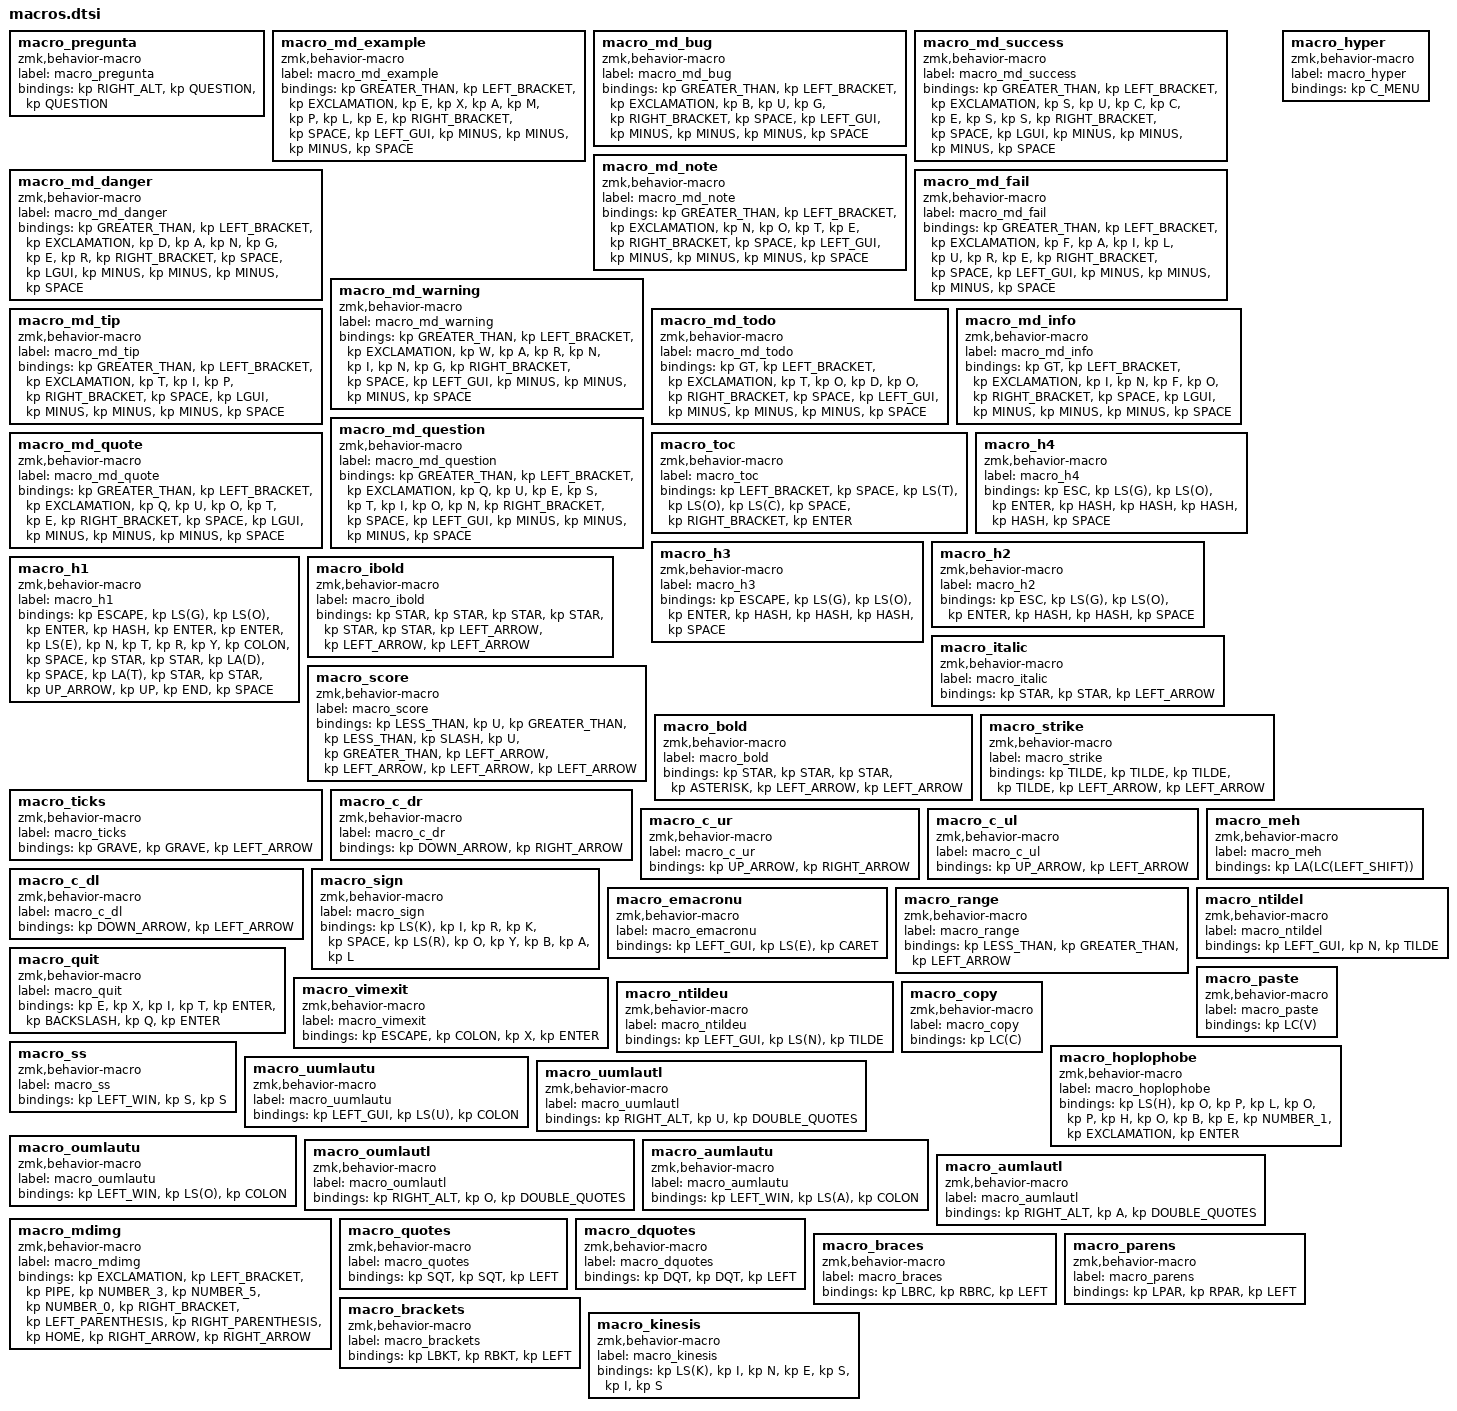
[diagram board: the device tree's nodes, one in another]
macro_pregunta: macro_pregunta{
compatible = "zmk,behavior-macro";
label = "macro_pregunta";
#binding-cells = <0>;
bindings = <&kp RIGHT_ALT>, <&kp QUESTION>, <&kp QUESTION>;
};
macro_md_example: macro_md_example{
compatible = "zmk,behavior-macro";
label = "macro_md_example";
#binding-cells = <0>;
bindings = <&kp GREATER_THAN>, <&kp LEFT_BRACKET>, <&kp EXCLAMATION>, <&kp E>, <&kp X>, <&kp A>, <&kp M>, <&kp P>, <&kp L>, <&kp E>, <&kp RIGHT_BRACKET>, <&kp SPACE>, <&kp LEFT_GUI>, <&kp MINUS>, <&kp MINUS>, <&kp MINUS>, <&kp SPACE>;
};
macro_md_bug: macro_md_bug{
compatible = "zmk,behavior-macro";
label = "macro_md_bug";
#binding-cells = <0>;
bindings = <&kp GREATER_THAN>, <&kp LEFT_BRACKET>, <&kp EXCLAMATION>, <&kp B>, <&kp U>, <&kp G>, <&kp RIGHT_BRACKET>, <&kp SPACE>, <&kp LEFT_GUI>, <&kp MINUS>, <&kp MINUS>, <&kp MINUS>, <&kp SPACE>;
};
macro_md_success: macro_md_success{
compatible = "zmk,behavior-macro";
label = "macro_md_success";
#binding-cells = <0>;
bindings = <&kp GREATER_THAN>, <&kp LEFT_BRACKET>, <&kp EXCLAMATION>, <&kp S>, <&kp U>, <&kp C>, <&kp C>, <&kp E>, <&kp S>, <&kp S>, <&kp RIGHT_BRACKET>, <&kp SPACE>, <&kp LGUI>, <&kp MINUS>, <&kp MINUS>, <&kp MINUS>, <&kp SPACE>;
};
macro_md_note: macro_md_note{
compatible = "zmk,behavior-macro";
label = "macro_md_note";
#binding-cells = <0>;
bindings = <&kp GREATER_THAN>, <&kp LEFT_BRACKET>, <&kp EXCLAMATION>, <&kp N>, <&kp O>, <&kp T>, <&kp E>, <&kp RIGHT_BRACKET>, <&kp SPACE>, <&kp LEFT_GUI>, <&kp MINUS>, <&kp MINUS>, <&kp MINUS>, <&kp SPACE>;
};
macro_md_danger: macro_md_danger{
compatible = "zmk,behavior-macro";
label = "macro_md_danger";
#binding-cells = <0>;
bindings = <&kp GREATER_THAN>, <&kp LEFT_BRACKET>, <&kp EXCLAMATION>, <&kp D>, <&kp A>, <&kp N>, <&kp G>, <&kp E>, <&kp R>, <&kp RIGHT_BRACKET>, <&kp SPACE>, <&kp LGUI>, <&kp MINUS>, <&kp MINUS>, <&kp MINUS>, <&kp SPACE>;
};
macro_md_fail: macro_md_fail{
compatible = "zmk,behavior-macro";
label = "macro_md_fail";
#binding-cells = <0>;
bindings = <&kp GREATER_THAN>, <&kp LEFT_BRACKET>, <&kp EXCLAMATION>, <&kp F>, <&kp A>, <&kp I>, <&kp L>, <&kp U>, <&kp R>, <&kp E>, <&kp RIGHT_BRACKET>, <&kp SPACE>, <&kp LEFT_GUI>, <&kp MINUS>, <&kp MINUS>, <&kp MINUS>, <&kp SPACE>;
};
macro_md_warning: macro_md_warning{
compatible = "zmk,behavior-macro";
label = "macro_md_warning";
#binding-cells = <0>;
bindings = <&kp GREATER_THAN>, <&kp LEFT_BRACKET>, <&kp EXCLAMATION>, <&kp W>, <&kp A>, <&kp R>, <&kp N>, <&kp I>, <&kp N>, <&kp G>, <&kp RIGHT_BRACKET>, <&kp SPACE>, <&kp LEFT_GUI>, <&kp MINUS>, <&kp MINUS>, <&kp MINUS>, <&kp SPACE>;
};
macro_md_tip: macro_md_tip{
compatible = "zmk,behavior-macro";
label = "macro_md_tip";
#binding-cells = <0>;
bindings = <&kp GREATER_THAN>, <&kp LEFT_BRACKET>, <&kp EXCLAMATION>, <&kp T>, <&kp I>, <&kp P>, <&kp RIGHT_BRACKET>, <&kp SPACE>, <&kp LGUI>, <&kp MINUS>, <&kp MINUS>, <&kp MINUS>, <&kp SPACE>;
};
macro_md_todo: macro_md_todo{
compatible = "zmk,behavior-macro";
label = "macro_md_todo";
#binding-cells = <0>;
bindings = <&kp GT>, <&kp LEFT_BRACKET>, <&kp EXCLAMATION>, <&kp T>, <&kp O>, <&kp D>, <&kp O>, <&kp RIGHT_BRACKET>, <&kp SPACE>, <&kp LEFT_GUI>, <&kp MINUS>, <&kp MINUS>, <&kp MINUS>, <&kp SPACE>;
};
macro_md_info: macro_md_info{
compatible = "zmk,behavior-macro";
label = "macro_md_info";
#binding-cells = <0>;
bindings = <&kp GT>, <&kp LEFT_BRACKET>, <&kp EXCLAMATION>, <&kp I>, <&kp N>, <&kp F>, <&kp O>, <&kp RIGHT_BRACKET>, <&kp SPACE>, <&kp LGUI>, <&kp MINUS>, <&kp MINUS>, <&kp MINUS>, <&kp SPACE>;
};
macro_md_question: macro_md_question{
compatible = "zmk,behavior-macro";
label = "macro_md_question";
#binding-cells = <0>;
bindings = <&kp GREATER_THAN>, <&kp LEFT_BRACKET>, <&kp EXCLAMATION>, <&kp Q>, <&kp U>, <&kp E>, <&kp S>, <&kp T>, <&kp I>, <&kp O>, <&kp N>, <&kp RIGHT_BRACKET>, <&kp SPACE>, <&kp LEFT_GUI>, <&kp MINUS>, <&kp MINUS>, <&kp MINUS>, <&kp SPACE>;
};
macro_md_quote: macro_md_quote{
compatible = "zmk,behavior-macro";
label = "macro_md_quote";
#binding-cells = <0>;
bindings = <&kp GREATER_THAN>, <&kp LEFT_BRACKET>, <&kp EXCLAMATION>, <&kp Q>, <&kp U>, <&kp O>, <&kp T>, <&kp E>, <&kp RIGHT_BRACKET>, <&kp SPACE>, <&kp LGUI>, <&kp MINUS>, <&kp MINUS>, <&kp MINUS>, <&kp SPACE>;
};
macro_toc: macro_toc{
compatible = "zmk,behavior-macro";
label = "macro_toc";
#binding-cells = <0>;
bindings = <&kp LEFT_BRACKET>, <&kp SPACE>, <&kp LS(T)>, <&kp LS(O)>, <&kp LS(C)>, <&kp SPACE>, <&kp RIGHT_BRACKET>, <&kp ENTER>;
};
macro_h4: macro_h4{
compatible = "zmk,behavior-macro";
label = "macro_h4";
#binding-cells = <0>;
bindings = <&kp ESC>, <&kp LS(G)>, <&kp LS(O)>, <&kp ENTER>, <&kp HASH>, <&kp HASH>, <&kp HASH>, <&kp HASH>, <&kp SPACE>;
};
macro_h3: macro_h3{
compatible = "zmk,behavior-macro";
label = "macro_h3";
#binding-cells = <0>;
bindings = <&kp ESCAPE>, <&kp LS(G)>, <&kp LS(O)>, <&kp ENTER>, <&kp HASH>, <&kp HASH>, <&kp HASH>, <&kp SPACE>;
};
macro_h2: macro_h2{
compatible = "zmk,behavior-macro";
label = "macro_h2";
#binding-cells = <0>;
bindings = <&kp ESC>, <&kp LS(G)>, <&kp LS(O)>, <&kp ENTER>, <&kp HASH>, <&kp HASH>, <&kp SPACE>;
};
macro_h1: macro_h1{
compatible = "zmk,behavior-macro";
label = "macro_h1";
#binding-cells = <0>;
bindings = <&kp ESCAPE>, <&kp LS(G)>, <&kp LS(O)>, <&kp ENTER>, <&kp HASH>, <&kp ENTER>, <&kp ENTER>, <&kp LS(E)>, <&kp N>, <&kp T>, <&kp R>, <&kp Y>, <&kp COLON>, <&kp SPACE>, <&kp STAR>, <&kp STAR>, <&kp LA(D)>, <&kp SPACE>, <&kp LA(T)>, <&kp STAR>, <&kp STAR>, <&kp UP_ARROW>, <&kp UP>, <&kp END>, <&kp SPACE>;
};
macro_ibold: macro_ibold{
compatible = "zmk,behavior-macro";
label = "macro_ibold";
#binding-cells = <0>;
bindings = <&kp STAR>, <&kp STAR>, <&kp STAR>, <&kp STAR>, <&kp STAR>, <&kp STAR>, <&kp LEFT_ARROW>, <&kp LEFT_ARROW>, <&kp LEFT_ARROW>;
};
macro_italic: macro_italic{
compatible = "zmk,behavior-macro";
label = "macro_italic";
#binding-cells = <0>;
bindings = <&kp STAR>, <&kp STAR>, <&kp LEFT_ARROW>;
};
macro_score: macro_score{
compatible = "zmk,behavior-macro";
label = "macro_score";
#binding-cells = <0>;
bindings = <&kp LESS_THAN>, <&kp U>, <&kp GREATER_THAN>, <&kp LESS_THAN>, <&kp SLASH>, <&kp U>, <&kp GREATER_THAN>, <&kp LEFT_ARROW>, <&kp LEFT_ARROW>, <&kp LEFT_ARROW>, <&kp LEFT_ARROW>;
};
macro_bold: macro_bold{
compatible = "zmk,behavior-macro";
label = "macro_bold";
#binding-cells = <0>;
bindings = <&kp STAR>, <&kp STAR>, <&kp STAR>, <&kp ASTERISK>, <&kp LEFT_ARROW>, <&kp LEFT_ARROW>;
};
macro_strike: macro_strike{
compatible = "zmk,behavior-macro";
label = "macro_strike";
#binding-cells = <0>;
bindings = <&kp TILDE>, <&kp TILDE>, <&kp TILDE>, <&kp TILDE>, <&kp LEFT_ARROW>, <&kp LEFT_ARROW>;
};
macro_ticks: macro_ticks{
compatible = "zmk,behavior-macro";
label = "macro_ticks";
#binding-cells = <0>;
bindings = <&kp GRAVE>, <&kp GRAVE>, <&kp LEFT_ARROW>;
};
macro_c_dr: macro_c_dr{
compatible = "zmk,behavior-macro";
label = "macro_c_dr";
#binding-cells = <0>;
bindings = <&kp DOWN_ARROW>, <&kp RIGHT_ARROW>;
};
macro_c_ur: macro_c_ur{
compatible = "zmk,behavior-macro";
label = "macro_c_ur";
#binding-cells = <0>;
bindings = <&kp UP_ARROW>, <&kp RIGHT_ARROW>;
};
macro_c_ul: macro_c_ul{
compatible = "zmk,behavior-macro";
label = "macro_c_ul";
#binding-cells = <0>;
bindings = <&kp UP_ARROW>, <&kp LEFT_ARROW>;
};
macro_c_dl: macro_c_dl{
compatible = "zmk,behavior-macro";
label = "macro_c_dl";
#binding-cells = <0>;
bindings = <&kp DOWN_ARROW>, <&kp LEFT_ARROW>;
};
macro_sign: macro_sign{
compatible = "zmk,behavior-macro";
label = "macro_sign";
#binding-cells = <0>;
bindings = <&kp LS(K)>, <&kp I>, <&kp R>, <&kp K>, <&kp SPACE>, <&kp LS(R)>, <&kp O>, <&kp Y>, <&kp B>, <&kp A>, <&kp L>;
};
macro_emacronu: macro_emacronu{
compatible = "zmk,behavior-macro";
label = "macro_emacronu";
#binding-cells = <0>;
bindings = <&kp LEFT_GUI>, <&kp LS(E)>, <&kp CARET>;
};
macro_range: macro_range{
compatible = "zmk,behavior-macro";
label = "macro_range";
#binding-cells = <0>;
bindings = <&kp LESS_THAN>, <&kp GREATER_THAN>, <&kp LEFT_ARROW>;
};
macro_hyper: macro_hyper{
compatible = "zmk,behavior-macro";
label = "macro_hyper";
#binding-cells = <0>;
bindings = <&kp C_MENU>;
};
macro_meh: macro_meh{
compatible = "zmk,behavior-macro";
label = "macro_meh";
#binding-cells = <0>;
bindings = <&kp LA(LC(LEFT_SHIFT))>;
};
macro_quit: macro_quit{
compatible = "zmk,behavior-macro";
label = "macro_quit";
#binding-cells = <0>;
bindings = <&kp E>, <&kp X>, <&kp I>, <&kp T>, <&kp ENTER>, <&kp BACKSLASH>, <&kp Q>, <&kp ENTER>;
};
macro_vimexit: macro_vimexit{
compatible = "zmk,behavior-macro";
label = "macro_vimexit";
#binding-cells = <0>;
bindings = <&kp ESCAPE>, <&kp COLON>, <&kp X>, <&kp ENTER>;
};
macro_ntildeu: macro_ntildeu{
compatible = "zmk,behavior-macro";
label = "macro_ntildeu";
#binding-cells = <0>;
bindings = <&kp LEFT_GUI>, <&kp LS(N)>, <&kp TILDE>;
};
macro_ntildel: macro_ntildel{
compatible = "zmk,behavior-macro";
label = "macro_ntildel";
#binding-cells = <0>;
bindings = <&kp LEFT_GUI>, <&kp N>, <&kp TILDE>;
};
macro_paste: macro_paste{
compatible = "zmk,behavior-macro";
label = "macro_paste";
#binding-cells = <0>;
bindings = <&kp LC(V)>;
};
macro_copy: macro_copy{
compatible = "zmk,behavior-macro";
label = "macro_copy";
#binding-cells = <0>;
bindings = <&kp LC(C)>;
};
macro_hoplophobe: macro_hoplophobe{
compatible = "zmk,behavior-macro";
label = "macro_hoplophobe";
#binding-cells = <0>;
bindings = <&kp LS(H)>, <&kp O>, <&kp P>, <&kp L>, <&kp O>, <&kp P>, <&kp H>, <&kp O>, <&kp B>, <&kp E>, <&kp NUMBER_1>, <&kp EXCLAMATION>, <&kp ENTER>;
};
macro_ss: macro_ss{
compatible = "zmk,behavior-macro";
label = "macro_ss";
#binding-cells = <0>;
bindings = <&kp LEFT_WIN>, <&kp S>, <&kp S>;
};
macro_uumlautu: macro_uumlautu{
compatible = "zmk,behavior-macro";
label = "macro_uumlautu";
#binding-cells = <0>;
bindings = <&kp LEFT_GUI>, <&kp LS(U)>, <&kp COLON>;
};
macro_uumlautl: macro_uumlautl{
compatible = "zmk,behavior-macro";
label = "macro_uumlautl";
#binding-cells = <0>;
bindings = <&kp RIGHT_ALT>, <&kp U>, <&kp DOUBLE_QUOTES>;
};
macro_oumlautu: macro_oumlautu{
compatible = "zmk,behavior-macro";
label = "macro_oumlautu";
#binding-cells = <0>;
bindings = <&kp LEFT_WIN>, <&kp LS(O)>, <&kp COLON>;
};
macro_oumlautl: macro_oumlautl{
compatible = "zmk,behavior-macro";
label = "macro_oumlautl";
#binding-cells = <0>;
bindings = <&kp RIGHT_ALT>, <&kp O>, <&kp DOUBLE_QUOTES>;
};
macro_aumlautu: macro_aumlautu{
compatible = "zmk,behavior-macro";
label = "macro_aumlautu";
#binding-cells = <0>;
bindings = <&kp LEFT_WIN>, <&kp LS(A)>, <&kp COLON>;
};
macro_aumlautl: macro_aumlautl{
compatible = "zmk,behavior-macro";
label = "macro_aumlautl";
#binding-cells = <0>;
bindings = <&kp RIGHT_ALT>, <&kp A>, <&kp DOUBLE_QUOTES>;
};
macro_mdimg: macro_mdimg{
compatible = "zmk,behavior-macro";
label = "macro_mdimg";
#binding-cells = <0>;
bindings = <&kp EXCLAMATION>, <&kp LEFT_BRACKET>, <&kp PIPE>, <&kp NUMBER_3>, <&kp NUMBER_5>, <&kp NUMBER_0>, <&kp RIGHT_BRACKET>, <&kp LEFT_PARENTHESIS>, <&kp RIGHT_PARENTHESIS>, <&kp HOME>, <&kp RIGHT_ARROW>, <&kp RIGHT_ARROW>;
};
macro_quotes: macro_quotes{
compatible = "zmk,behavior-macro";
label = "macro_quotes";
#binding-cells = <0>;
bindings = <&kp SQT>, <&kp SQT>, <&kp LEFT>;
};
macro_dquotes: macro_dquotes{
compatible = "zmk,behavior-macro";
label = "macro_dquotes";
#binding-cells = <0>;
bindings = <&kp DQT>, <&kp DQT>, <&kp LEFT>;
};
macro_braces: macro_braces{
compatible = "zmk,behavior-macro";
label = "macro_braces";
#binding-cells = <0>;
bindings = <&kp LBRC>, <&kp RBRC>, <&kp LEFT>;
};
macro_parens: macro_parens{
compatible = "zmk,behavior-macro";
label = "macro_parens";
#binding-cells = <0>;
bindings = <&kp LPAR>, <&kp RPAR>, <&kp LEFT>;
};
macro_brackets: macro_brackets{
compatible = "zmk,behavior-macro";
label = "macro_brackets";
#binding-cells = <0>;
bindings = <&kp LBKT>, <&kp RBKT>, <&kp LEFT>;
};
macro_kinesis: macro_kinesis{
compatible = "zmk,behavior-macro";
label = "macro_kinesis";
#binding-cells = <0>;
bindings = <&kp LS(K)>, <&kp I>, <&kp N>, <&kp E>, <&kp S>, <&kp I>, <&kp S>;
};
